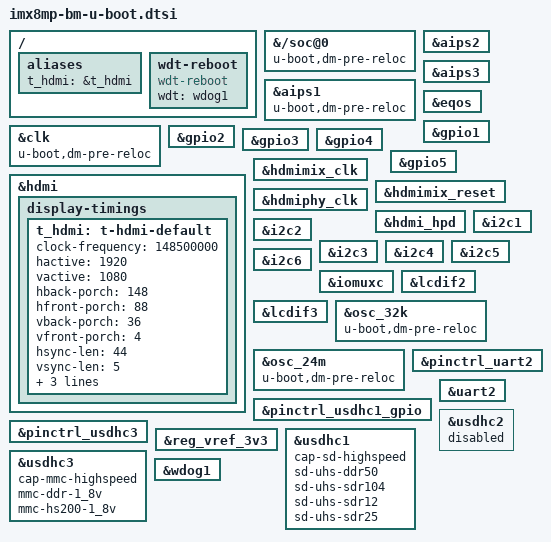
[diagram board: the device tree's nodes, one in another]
// SPDX-License-Identifier: GPL-2.0+
/*
 * Copyright 2019 NXP
 */
#include "imx8mp-u-boot.dtsi"

/ {
	aliases {
		t_hdmi = &t_hdmi;
	};

	wdt-reboot {
		compatible = "wdt-reboot";
		wdt = <&wdog1>;
		u-boot,dm-spl;
	};
};

&{/soc@0} {
	u-boot,dm-pre-reloc;
	u-boot,dm-spl;
};

&aips1 {
	u-boot,dm-spl;
	u-boot,dm-pre-reloc;
};

&aips2 {
	u-boot,dm-spl;
};

&aips3 {
	u-boot,dm-spl;
};

&clk {
	u-boot,dm-spl;
	u-boot,dm-pre-reloc;
};

&eqos {
	/delete-property/ assigned-clocks;
	/delete-property/ assigned-clock-parents;
	/delete-property/ assigned-clock-rates;
};

&gpio1 {
	u-boot,dm-spl;
};

&gpio2 {
	u-boot,dm-spl;
};

&gpio3 {
	u-boot,dm-spl;
};

&gpio4 {
	u-boot,dm-spl;
};

&gpio5 {
	u-boot,dm-spl;
};

&hdmi {
	display-timings {
		t_hdmi: t-hdmi-default {
			/* m101nwwb by default */
			clock-frequency = <148500000>;
			hactive = <1920>;
			vactive = <1080>;
			hback-porch = <148>;
			hfront-porch = <88>;
			vback-porch = <36>;
			vfront-porch = <4>;
			hsync-len = <44>;
			vsync-len = <5>;
			hsync-active = <1>;
			vsync-active = <1>;
			de-active = <1>;
		};
	};
};

&hdmimix_clk {
	status = "okay";
};

&hdmimix_reset {
	status = "okay";
};

&hdmiphy_clk {
	status = "okay";
};

&hdmi_hpd {
	status = "okay";
};

&i2c1 {
	u-boot,dm-spl;
};

&i2c2 {
	u-boot,dm-spl;
};

&i2c3 {
	u-boot,dm-spl;
};

&i2c4 {
	u-boot,dm-spl;
};

&i2c5 {
	u-boot,dm-spl;
};

&i2c6 {
	u-boot,dm-spl;
};

&iomuxc {
	u-boot,dm-spl;
};

&lcdif2 {
	status = "okay";
};

&lcdif3 {
	status = "okay";
};

&osc_32k {
	u-boot,dm-spl;
	u-boot,dm-pre-reloc;
};

&osc_24m {
	u-boot,dm-spl;
	u-boot,dm-pre-reloc;
};

&pinctrl_uart2 {
	u-boot,dm-spl;
};

&pinctrl_usdhc1_gpio {
	u-boot,dm-spl;
};

&pinctrl_usdhc3 {
	u-boot,dm-spl;
};

&reg_vref_3v3 {
	u-boot,dm-spl;
};

&uart2 {
	u-boot,dm-spl;
};

&usdhc1 {
	cap-sd-highspeed;
	sd-uhs-ddr50;
	sd-uhs-sdr104;
	sd-uhs-sdr12;
	sd-uhs-sdr25;
	u-boot,dm-spl;
};

&usdhc2 {
	status = "disabled";
};

&usdhc3 {
	cap-mmc-highspeed;
	mmc-ddr-1_8v;
	mmc-hs200-1_8v;
	u-boot,dm-spl;
};

&wdog1 {
	u-boot,dm-spl;
};
